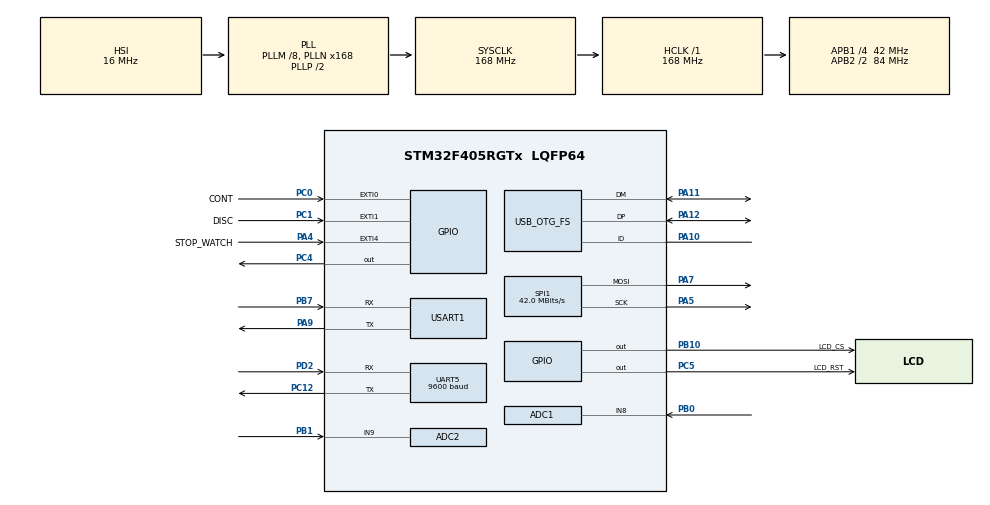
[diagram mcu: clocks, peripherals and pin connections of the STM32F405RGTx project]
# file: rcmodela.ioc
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ADC1.Channel-0\#ChannelRegularConversion=ADC_CHANNEL_8
ADC1.NbrOfConversionFlag=1
ADC1.Rank-0\#ChannelRegularConversion=1
ADC1.SamplingTime-0\#ChannelRegularConversion=ADC_SAMPLETIME_15CYCLES
ADC1.master=1
ADC2.Channel-0\#ChannelRegularConversion=ADC_CHANNEL_9
ADC2.NbrOfConversionFlag=1
ADC2.Rank-0\#ChannelRegularConversion=1
ADC2.SamplingTime-0\#ChannelRegularConversion=ADC_SAMPLETIME_15CYCLES
Dma.Request0=SPI1_TX
Dma.SPI1_TX.0.Direction=DMA_MEMORY_TO_PERIPH
Dma.SPI1_TX.0.FIFOMode=DMA_FIFOMODE_DISABLE
Dma.SPI1_TX.0.Instance=DMA2_Stream3
Dma.SPI1_TX.0.MemDataAlignment=DMA_MDATAALIGN_BYTE
Dma.SPI1_TX.0.MemInc=DMA_MINC_ENABLE
Dma.SPI1_TX.0.Mode=DMA_NORMAL
Dma.SPI1_TX.0.PeriphDataAlignment=DMA_PDATAALIGN_BYTE
Dma.SPI1_TX.0.PeriphInc=DMA_PINC_DISABLE
Dma.SPI1_TX.0.Priority=DMA_PRIORITY_LOW
Mcu.Family=STM32F4
Mcu.Name=STM32F405RGTx
Mcu.Package=LQFP64
NVIC.DMA2_Stream3_IRQn=true\:0\:0\:false\:false\:true\:false\:true\:true
NVIC.EXTI0_IRQn=true\:0\:0\:false\:false\:true\:true\:true\:true
NVIC.EXTI1_IRQn=true\:0\:0\:false\:false\:true\:true\:true\:true
NVIC.EXTI4_IRQn=true\:0\:0\:false\:false\:true\:true\:true\:true
NVIC.PriorityGroup=NVIC_PRIORITYGROUP_4
NVIC.TIM2_IRQn=true\:0\:0\:false\:false\:true\:true\:true\:true
PA10.Mode=OTG/Dual_Role_Device
PA10.Signal=USB_OTG_FS_ID
PA11.Mode=OTG/Dual_Role_Device
PA11.Signal=USB_OTG_FS_DM
PA12.Mode=OTG/Dual_Role_Device
PA12.Signal=USB_OTG_FS_DP
PA4.GPIO_Label=STOP_WATCH
PA4.GPIO_ModeDefaultEXTI=GPIO_MODE_IT_FALLING
PA4.GPIO_PuPd=GPIO_PULLUP
PA4.Signal=GPXTI4
PA5.Mode=TX_Only_Simplex_Unidirect_Master
PA5.Signal=SPI1_SCK
PA7.Mode=TX_Only_Simplex_Unidirect_Master
PA7.Signal=SPI1_MOSI
PA9.Mode=Asynchronous
PA9.Signal=USART1_TX
PB0.Signal=ADCx_IN8
PB1.Signal=ADCx_IN9
PB10.GPIO_Label=LCD_CS
PB10.GPIO_PuPd=GPIO_PULLUP
PB10.GPIO_Speed=GPIO_SPEED_FREQ_HIGH
PB10.PinState=GPIO_PIN_SET
PB10.Signal=GPIO_Output
PB7.Mode=Asynchronous
PB7.Signal=USART1_RX
PC0.GPIO_Label=CONT
PC0.GPIO_ModeDefaultEXTI=GPIO_MODE_IT_FALLING
PC0.GPIO_PuPd=GPIO_PULLUP
PC0.Signal=GPXTI0
PC1.GPIO_Label=DISC
PC1.GPIO_ModeDefaultEXTI=GPIO_MODE_IT_FALLING
PC1.GPIO_PuPd=GPIO_PULLUP
PC1.Signal=GPXTI1
PC12.Mode=Asynchronous
PC12.Signal=UART5_TX
PC4.Signal=GPIO_Output
PC5.GPIO_Label=LCD_RST
PC5.GPIO_PuPd=GPIO_PULLUP
PC5.GPIO_Speed=GPIO_SPEED_FREQ_HIGH
PC5.PinState=GPIO_PIN_SET
PC5.Signal=GPIO_Output
PD2.Mode=Asynchronous
PD2.Signal=UART5_RX
ProjectManager.HeapSize=0x200
ProjectManager.StackSize=0x400
ProjectManager.TargetToolchain=STM32CubeIDE
RCC.48MHZClocksFreq_Value=84000000
RCC.AHBFreq_Value=168000000
RCC.APB1CLKDivider=RCC_HCLK_DIV4
RCC.APB1Freq_Value=42000000
RCC.APB1TimFreq_Value=84000000
RCC.APB2CLKDivider=RCC_HCLK_DIV2
RCC.APB2Freq_Value=84000000
RCC.APB2TimFreq_Value=168000000
RCC.CortexFreq_Value=168000000
RCC.HCLKFreq_Value=168000000
RCC.HSE_VALUE=25000000
RCC.HSI_VALUE=16000000
RCC.LSE_VALUE=32768
RCC.PLLM=8
RCC.PLLN=168
RCC.PLLSourceVirtualString=RCC_PLLSOURCE_HSI
RCC.SYSCLKFreq_VALUE=168000000
RCC.SYSCLKSource=RCC_SYSCLKSOURCE_PLLCLK
RCC.VCOOutputFreq_Value=336000000
SH.ADCx_IN8.0=ADC1_IN8,IN8
SH.ADCx_IN9.0=ADC2_IN9,IN9
SPI1.BaudRatePrescaler=SPI_BAUDRATEPRESCALER_2
SPI1.CalculateBaudRate=42.0 MBits/s
SPI1.Direction=SPI_DIRECTION_2LINES
SPI1.Mode=SPI_MODE_MASTER
SPI1.VirtualType=VM_MASTER
TIM2.Period=10000-1
TIM2.Prescaler=16800-1
UART5.BaudRate=9600
UART5.VirtualMode=Asynchronous
USART1.VirtualMode=VM_ASYNC
VP_TIM2_VS_ClockSourceINT.Mode=Internal
board=custom

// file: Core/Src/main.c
/* USER CODE BEGIN Header */
/**
  ******************************************************************************
  * @file           : main.c
  * @brief          : Main program body
  ******************************************************************************
  * @attention
  *
  * Copyright (c) 2025 STMicroelectronics.
  * All rights reserved.
  *
  * This software is licensed under terms that can be found in the LICENSE file
  * in the root directory of this software component.
  * If no LICENSE file comes with this software, it is provided AS-IS.
  *
  ******************************************************************************
  */
/* USER CODE END Header */
#include "main.h"

/* USER CODE BEGIN Includes */
#include "ILI9341_STM32_DRIVER.h"
#include "ILI9341_GFX.h"
#include "stdio.h"
#include "stdlib.h"
#include "Corrected_U8_Image.h"
#include "ryrl898.h"
#include "stopwatch.h"
#include "allpic.h"

/* USER CODE END Includes */

/* Battery & Sensor Parameters */
#define BATTERY_CAPACITY_AH       2.5f       // 2500 mAh
#define ADC_VREF_VOLTAGE          3.3f       // Reference voltage of ADC
#define ADC_RESOLUTION            4096.0f    // 12-bit ADC
#define VCC_VOLTAGE               3.3f       // ACS712 supply voltage
#define ACS712_SENSITIVITY        0.100f     // V/A for ACS712-20A (100 mV/A)
#define ACS712_OFFSET_VOLTAGE     (VCC_VOLTAGE/2.0f) // zero current voltage
#define TIM2_TICK_PERIOD_S        1.0f       // Timer callback period in seconds

/* USER CODE BEGIN PM */
// #define Total_Cap 2.5           //2500mAh
// #define Vcc 3.3                 //3.6 Max
// #define ACS712_Sensitivity 0.1  //100 mV/A
// #define ADC_Vref 3.3          // max 3.6v
// #define ADC_Resolution 4096  //12-bit Regitser

/* USER CODE END PM */

ADC_HandleTypeDef hadc1;
ADC_HandleTypeDef hadc2;

SPI_HandleTypeDef hspi1;
DMA_HandleTypeDef hdma_spi1_tx;

TIM_HandleTypeDef htim2;

UART_HandleTypeDef huart5;
UART_HandleTypeDef huart1;

uint16_t counter_exti4 =0;

uint8_t mins_stopwatch = 0;
uint8_t sec_stopwatch = 0 ;
uint8_t stopwatch_screen_flag=0;

uint8_t soc_joky; //This Variable will receive the updated Jokey soc sent by the Jokey system via LoRa.

uint8_t soc_rc;
float ACS712_Current;
float ACS712_Voltage;
char timer_text[9];
//char soc_rc_text[3];
char soc_joky_text[3];
char soc_str[10];

void SystemClock_Config(void);
static void MX_GPIO_Init(void);
static void MX_DMA_Init(void);
static void MX_SPI1_Init(void);
static void MX_TIM2_Init(void);
static void MX_UART5_Init(void);
static void MX_USART1_UART_Init(void);
static void MX_ADC1_Init(void);
static void MX_ADC2_Init(void);
void Display_LCD_UI(void);

/* USER CODE BEGIN 0 */
void HAL_GPIO_EXTI_Callback(uint16_t GPIO_Pin)
{
    if(GPIO_Pin == GPIO_PIN_0)  // Check which pin triggered the EXTI
    {
    	//HAL_NVIC_DisableIRQ(EXTI0_IRQn);  // Disable EXTI Line 0 interrupt

        // Your EXTI handling code here
        //do somthing
        //HAL_NVIC_EnableIRQ(EXTI0_IRQn);

    }
    else if(GPIO_Pin == GPIO_PIN_1){

    }
    else if(GPIO_Pin == GPIO_PIN_4){
    HAL_NVIC_DisableIRQ(EXTI4_IRQn);
        HAL_Delay(600);
        if(!HAL_GPIO_ReadPin(STOP_WATCH_GPIO_Port, STOP_WATCH_Pin)){
            counter_exti4 = 0; mins_stopwatch = 0; sec_stopwatch = 0; stopwatch_screen_flag = 0;
            // ILI9341_DrawText("00 : 00", FONT3, 90 , 260, WHITE, BLACK);
            ILI9341_DrawText("00:00", FONT4, 100, 280, WHITE, BLACK);              // Timer text

        }
    	counter_exti4++;
    	if((counter_exti4%2) == 0){
    		stopwatch_screen_flag=0;
    	}

    	else{
    		stopwatch_screen_flag=1;
    	}

    	//        //do somthing
    	//        // Your EXTI ha
        HAL_NVIC_EnableIRQ(EXTI4_IRQn);
    }
}

void HAL_TIM_PeriodElapsedCallback(TIM_HandleTypeDef *htim)
{
    if(htim->Instance == TIM2)
    {
        // Stopwatch update
        if(stopwatch_screen_flag == 1)
        {
            sec_stopwatch++;
            if(sec_stopwatch == 60) { sec_stopwatch = 0; mins_stopwatch++; }
             if(mins_stopwatch == 99) { sec_stopwatch = 0; stopwatch_screen_flag = 0; }

            // sprintf(timer_text,"%d : %d", mins_stopwatch, sec_stopwatch);
            sprintf(timer_text,"%02d : %02d", mins_stopwatch, sec_stopwatch);
            ILI9341_DrawText((const char*)timer_text, FONT4, 100, 280, WHITE, BLACK);
            // ILI9341_DrawText((const char*)timer_text, FONT3, 90 , 260, WHITE, BLACK);
        }

        // Battery SOC calculation
        static float Remain_Cap = BATTERY_CAPACITY_AH; // assume full at boot
        static uint8_t soc_rc_temp = 255;              // force first update
        static uint8_t soc_joky_temp = 255;

        // Read current from ADC
        HAL_ADC_Start(&hadc1);
        HAL_ADC_PollForConversion(&hadc1, 10);
        uint16_t adc_val = HAL_ADC_GetValue(&hadc1);
        HAL_ADC_Stop(&hadc1);

        ACS712_Voltage = ((adc_val * ADC_VREF_VOLTAGE) / ADC_RESOLUTION);
        ACS712_Current = (ACS712_Voltage - ACS712_OFFSET_VOLTAGE) / ACS712_SENSITIVITY;

        // Integrate current to calculate remaining capacity (Ah)
        float delta_Ah = ACS712_Current * (TIM2_TICK_PERIOD_S / 3600.0f);
        Remain_Cap += delta_Ah;

        // Clamp capacity
        if(Remain_Cap > BATTERY_CAPACITY_AH) Remain_Cap = BATTERY_CAPACITY_AH;
        if(Remain_Cap < 0.0f) Remain_Cap = 0.0f;

        soc_rc = (Remain_Cap / BATTERY_CAPACITY_AH) * 100.0f;

        // Update SOC display if changed
        if((uint8_t)soc_rc != soc_rc_temp)
        {
//            sprintf(soc_rc_text, "%d", (uint8_t)soc_rc);
            ILI9341_DrawText((const char*)soc_str, FONT3, 60 ,100, WHITE, BLACK);
            soc_rc_temp = (uint8_t)soc_rc;
            sprintf(soc_str, "%d%%", soc_rc);
            ILI9341_DrawText((const char*)soc_str, FONT3, 70 ,100, WHITE, BLACK);
            if(soc_rc < 10){

                ILI9341_DrawImageAt((const uint8_t*)_less10, 20, 50, 30, 60);                                    // Battery icon

            }
            else if(soc_rc >= 20 && soc_rc < 35){
                ILI9341_DrawImageAt((const uint8_t*)_20, 20, 50, 30, 60);                                    // Battery icon
            }
            else if(soc_rc >= 35 && soc_rc < 50){
                ILI9341_DrawImageAt((const uint8_t*)_35, 20, 50, 30, 60);                                    // Battery icon
            }
            else if(soc_rc >= 50 && soc_rc < 65){
                ILI9341_DrawImageAt((const uint8_t*)_50, 20, 50, 30, 60);                                    // Battery icon
            }
            else if(soc_rc >= 65 && soc_rc < 85){
                ILI9341_DrawImageAt((const uint8_t*)_65, 20, 50, 30, 60);                                    // Battery icon
            }
            else if(soc_rc >= 85 && soc_rc < 100){
                ILI9341_DrawImageAt((const uint8_t*)_85, 20, 50, 30, 60);                                    // Battery icon
            }
            else if(soc_rc >= 100){
                ILI9341_DrawImageAt((const uint8_t*)_100, 20, 50, 30, 60);                                   // Battery icon
            }

        // Update Jokey SOC display if changed
        if(soc_joky != soc_joky_temp)
        {
          soc_joky_temp = soc_joky;
            // sprintf(soc_joky_text, "%d", soc_joky);
            sprintf(soc_joky_text, "%d%%", soc_joky);
            ILI9341_DrawText((const char*)soc_joky_text, FONT3, 180 ,100, WHITE, BLACK);
            //<<==================================================================>>//
            if(soc_joky < 10){

                ILI9341_DrawImageAt((const uint8_t*)_less10, 20, 50, 30, 60);                                    // Battery icon

            }
            else if(soc_joky >= 20 && soc_joky < 35){
                ILI9341_DrawImageAt((const uint8_t*)_20, 20, 50, 30, 60);                                    // Battery icon
            }
            else if(soc_joky >= 35 && soc_joky < 50){
                ILI9341_DrawImageAt((const uint8_t*)_35, 20, 50, 30, 60);                                    // Battery icon
            }
            else if(soc_joky >= 50 && soc_joky < 65){
                ILI9341_DrawImageAt((const uint8_t*)_50, 20, 50, 30, 60);                                    // Battery icon
            }
            else if(soc_joky >= 65 && soc_joky < 85){
                ILI9341_DrawImageAt((const uint8_t*)_65, 20, 50, 30, 60);                                    // Battery icon
            }
            else if(soc_joky >= 85 && soc_joky < 100){
                ILI9341_DrawImageAt((const uint8_t*)_85, 20, 50, 30, 60);                                    // Battery icon
            }
            else if(soc_joky >= 100){
                ILI9341_DrawImageAt((const uint8_t*)_100, 20, 50, 30, 60);                                   // Battery icon
            }

        }
    }
}
}

/* USER CODE END 0 */

int main(void)
{

  /* MCU Configuration--------------------------------------------------------*/

  /* Reset of all peripherals, Initializes the Flash interface and the Systick. */
  HAL_Init();

  /* Configure the system clock */
  SystemClock_Config();

  /* Initialize all configured peripherals */
  MX_GPIO_Init();
  MX_DMA_Init();
  MX_SPI1_Init();
  MX_TIM2_Init();
  MX_UART5_Init();
  MX_USART1_UART_Init();
  MX_ADC1_Init();
  MX_ADC2_Init();
  /* USER CODE BEGIN 2 */
      ILI9341_Init();
      HAL_Delay(100);
    Display_LCD_UI();
      HAL_TIM_Base_Start_IT(&htim2); // Start TIM2 interrupts

  /* USER CODE END 2 */
  uint32_t cont_count=0;
  /* Infinite loop */
  /* USER CODE BEGIN WHILE */
  while (1)
  {

	//code in background the lora and controllers in the poll mode

     /* USER CODE END WHILE */
	  if((!HAL_GPIO_ReadPin(CONT_GPIO_Port, CONT_Pin)) ||(!HAL_GPIO_ReadPin(DISC_GPIO_Port, DISC_Pin)) ){
		  if(!HAL_GPIO_ReadPin(CONT_GPIO_Port, CONT_Pin)){
			  if(cont_count%2==0){
			  lora_send_char((uint8_t)'c');
        soc_joky = lora_receive_char();
			  HAL_Delay(1000);}
			  else {
				  lora_send_char((uint8_t)'0');
          soc_joky = lora_receive_char();
				  HAL_Delay(1000);
			  }
			  cont_count++;

		  }
		  if(!HAL_GPIO_ReadPin(DISC_GPIO_Port, DISC_Pin)){
			  lora_send_char((uint8_t)'d');
        soc_joky = lora_receive_char();

			  HAL_Delay(1000);
		  }

	  }

  }
}

void Display_LCD_UI(void)
{
    // Clear screen
    ILI9341_FillScreen(BLACK);

    // === TOP BAR ===
    ILI9341_DrawText("AMER 1", FONT3, 10, 10, RED, BLACK);                   // Top-left code
    ILI9341_DrawImageAt((const uint8_t*)_4, 210, 10, 20, 20);                                      // Top-right signal icon

    // === BATTERY 1 (Left) ===
    ILI9341_DrawImageAt((const uint8_t*)_less10, 20, 50, 30, 60);                                    // Battery icon
    ILI9341_DrawText("100%", FONT4, 70, 70, WHITE, BLACK);                 // Battery percentage
//    ILI9341_DrawText("SOC_RC", FONT3, 20, 30, WHITE, BLACK);             // Device name

    // === BATTERY 2 (Right) ===
    ILI9341_DrawImageAt((const uint8_t*)_85, 140, 50, 30, 60);                                   // Battery icon
    ILI9341_DrawText("100%", FONT4, 190, 70, WHITE, BLACK);                // Battery percentage
//    ILI9341_DrawText("ROBOT ", FONT3, 140, 30, WHITE, BLACK);          // Device name

    // === DIVIDER ===
//    ILI9341_DrawHLine(0, 220, 240, WHITE);                                          // Horizontal line
//    ILI9341_DrawHLine(0, 221, 240, WHITE);                                          // Horizontal line
//    ILI9341_DrawHLine(0, 222, 240, WHITE);                                          // Horizontal line
//    ILI9341_DrawHLine(0, 222, 240, WHITE);                                          // Horizontal line

    // === STOPWATCH AREA ===
    ILI9341_DrawText("STOP-WATCH", FONT3, 75, 260, WHITE, BLACK);         // Label
    ILI9341_DrawText("00:00", FONT4, 100, 280, WHITE, BLACK);              // Timer text
    ILI9341_DrawImageAt((const uint8_t*)stopwatch, 95, 180, 50, 60);                                   // Stopwatch icon

}

void SystemClock_Config(void)
{
  RCC_OscInitTypeDef RCC_OscInitStruct = {0};
  RCC_ClkInitTypeDef RCC_ClkInitStruct = {0};

  /** Configure the main internal regulator output voltage
  */
  __HAL_RCC_PWR_CLK_ENABLE();
  __HAL_PWR_VOLTAGESCALING_CONFIG(PWR_REGULATOR_VOLTAGE_SCALE1);

  /** Initializes the RCC Oscillators according to the specified parameters
  * in the RCC_OscInitTypeDef structure.
  */
  RCC_OscInitStruct.OscillatorType = RCC_OSCILLATORTYPE_HSI;
  RCC_OscInitStruct.HSIState = RCC_HSI_ON;
  RCC_OscInitStruct.HSICalibrationValue = RCC_HSICALIBRATION_DEFAULT;
  RCC_OscInitStruct.PLL.PLLState = RCC_PLL_ON;
  RCC_OscInitStruct.PLL.PLLSource = RCC_PLLSOURCE_HSI;
  RCC_OscInitStruct.PLL.PLLM = 8;
  RCC_OscInitStruct.PLL.PLLN = 168;
  RCC_OscInitStruct.PLL.PLLP = RCC_PLLP_DIV2;
  RCC_OscInitStruct.PLL.PLLQ = 4;
  if (HAL_RCC_OscConfig(&RCC_OscInitStruct) != HAL_OK)
  {
    Error_Handler();
  }

  /** Initializes the CPU, AHB and APB buses clocks
  */
  RCC_ClkInitStruct.ClockType = RCC_CLOCKTYPE_HCLK|RCC_CLOCKTYPE_SYSCLK
                              |RCC_CLOCKTYPE_PCLK1|RCC_CLOCKTYPE_PCLK2;
  RCC_ClkInitStruct.SYSCLKSource = RCC_SYSCLKSOURCE_PLLCLK;
  RCC_ClkInitStruct.AHBCLKDivider = RCC_SYSCLK_DIV1;
  RCC_ClkInitStruct.APB1CLKDivider = RCC_HCLK_DIV4;
  RCC_ClkInitStruct.APB2CLKDivider = RCC_HCLK_DIV2;

  if (HAL_RCC_ClockConfig(&RCC_ClkInitStruct, FLASH_LATENCY_5) != HAL_OK)
  {
    Error_Handler();
  }
}

static void MX_ADC1_Init(void)
{

  ADC_ChannelConfTypeDef sConfig = {0};

  /** Configure the global features of the ADC (Clock, Resolution, Data Alignment and number of conversion)
  */
  hadc1.Instance = ADC1;
  hadc1.Init.ClockPrescaler = ADC_CLOCK_SYNC_PCLK_DIV4;
  hadc1.Init.Resolution = ADC_RESOLUTION_12B;
  hadc1.Init.ScanConvMode = DISABLE;
  hadc1.Init.ContinuousConvMode = DISABLE;
  hadc1.Init.DiscontinuousConvMode = DISABLE;
  hadc1.Init.ExternalTrigConvEdge = ADC_EXTERNALTRIGCONVEDGE_NONE;
  hadc1.Init.ExternalTrigConv = ADC_SOFTWARE_START;
  hadc1.Init.DataAlign = ADC_DATAALIGN_RIGHT;
  hadc1.Init.NbrOfConversion = 1;
  hadc1.Init.DMAContinuousRequests = DISABLE;
  hadc1.Init.EOCSelection = ADC_EOC_SINGLE_CONV;
  if (HAL_ADC_Init(&hadc1) != HAL_OK)
  {
    Error_Handler();
  }

  /** Configure for the selected ADC regular channel its corresponding rank in the sequencer and its sample time.
  */
  sConfig.Channel = ADC_CHANNEL_8;
  sConfig.Rank = 1;
  sConfig.SamplingTime = ADC_SAMPLETIME_15CYCLES;
  if (HAL_ADC_ConfigChannel(&hadc1, &sConfig) != HAL_OK)
  {
    Error_Handler();
  }

}

static void MX_ADC2_Init(void)
{

  ADC_ChannelConfTypeDef sConfig = {0};

  /** Configure the global features of the ADC (Clock, Resolution, Data Alignment and number of conversion)
  */
  hadc2.Instance = ADC2;
  hadc2.Init.ClockPrescaler = ADC_CLOCK_SYNC_PCLK_DIV4;
  hadc2.Init.Resolution = ADC_RESOLUTION_12B;
  hadc2.Init.ScanConvMode = DISABLE;
  hadc2.Init.ContinuousConvMode = DISABLE;
  hadc2.Init.DiscontinuousConvMode = DISABLE;
  hadc2.Init.ExternalTrigConvEdge = ADC_EXTERNALTRIGCONVEDGE_NONE;
  hadc2.Init.ExternalTrigConv = ADC_SOFTWARE_START;
  hadc2.Init.DataAlign = ADC_DATAALIGN_RIGHT;
  hadc2.Init.NbrOfConversion = 1;
  hadc2.Init.DMAContinuousRequests = DISABLE;
  hadc2.Init.EOCSelection = ADC_EOC_SINGLE_CONV;
  if (HAL_ADC_Init(&hadc2) != HAL_OK)
  {
    Error_Handler();
  }

  /** Configure for the selected ADC regular channel its corresponding rank in the sequencer and its sample time.
  */
  sConfig.Channel = ADC_CHANNEL_9;
  sConfig.Rank = 1;
  sConfig.SamplingTime = ADC_SAMPLETIME_15CYCLES;
  if (HAL_ADC_ConfigChannel(&hadc2, &sConfig) != HAL_OK)
  {
    Error_Handler();
  }

}

static void MX_SPI1_Init(void)
{

  /* SPI1 parameter configuration*/
  hspi1.Instance = SPI1;
  hspi1.Init.Mode = SPI_MODE_MASTER;
  hspi1.Init.Direction = SPI_DIRECTION_2LINES;
  hspi1.Init.DataSize = SPI_DATASIZE_8BIT;
  hspi1.Init.CLKPolarity = SPI_POLARITY_LOW;
  hspi1.Init.CLKPhase = SPI_PHASE_1EDGE;
  hspi1.Init.NSS = SPI_NSS_SOFT;
  hspi1.Init.BaudRatePrescaler = SPI_BAUDRATEPRESCALER_2;
  hspi1.Init.FirstBit = SPI_FIRSTBIT_MSB;
  hspi1.Init.TIMode = SPI_TIMODE_DISABLE;
  hspi1.Init.CRCCalculation = SPI_CRCCALCULATION_DISABLE;
  hspi1.Init.CRCPolynomial = 10;
  if (HAL_SPI_Init(&hspi1) != HAL_OK)
  {
    Error_Handler();
  }

}

static void MX_TIM2_Init(void)
{

  TIM_ClockConfigTypeDef sClockSourceConfig = {0};
  TIM_MasterConfigTypeDef sMasterConfig = {0};

  htim2.Instance = TIM2;
  htim2.Init.Prescaler = 16800-1;
  htim2.Init.CounterMode = TIM_COUNTERMODE_UP;
  htim2.Init.Period = 10000-1;
  htim2.Init.ClockDivision = TIM_CLOCKDIVISION_DIV1;
  htim2.Init.AutoReloadPreload = TIM_AUTORELOAD_PRELOAD_DISABLE;
  if (HAL_TIM_Base_Init(&htim2) != HAL_OK)
  {
    Error_Handler();
  }
  sClockSourceConfig.ClockSource = TIM_CLOCKSOURCE_INTERNAL;
  if (HAL_TIM_ConfigClockSource(&htim2, &sClockSourceConfig) != HAL_OK)
  {
    Error_Handler();
  }
  sMasterConfig.MasterOutputTrigger = TIM_TRGO_RESET;
  sMasterConfig.MasterSlaveMode = TIM_MASTERSLAVEMODE_DISABLE;
  if (HAL_TIMEx_MasterConfigSynchronization(&htim2, &sMasterConfig) != HAL_OK)
  {
    Error_Handler();
  }

}

static void MX_UART5_Init(void)
{

  huart5.Instance = UART5;
  huart5.Init.BaudRate = 9600;
  huart5.Init.WordLength = UART_WORDLENGTH_8B;
  huart5.Init.StopBits = UART_STOPBITS_1;
  huart5.Init.Parity = UART_PARITY_NONE;
  huart5.Init.Mode = UART_MODE_TX_RX;
  huart5.Init.HwFlowCtl = UART_HWCONTROL_NONE;
  huart5.Init.OverSampling = UART_OVERSAMPLING_16;
  if (HAL_UART_Init(&huart5) != HAL_OK)
  {
    Error_Handler();
  }

}

static void MX_USART1_UART_Init(void)
{

  huart1.Instance = USART1;
  huart1.Init.BaudRate = 115200;
  huart1.Init.WordLength = UART_WORDLENGTH_8B;
  huart1.Init.StopBits = UART_STOPBITS_1;
  huart1.Init.Parity = UART_PARITY_NONE;
  huart1.Init.Mode = UART_MODE_TX_RX;
  huart1.Init.HwFlowCtl = UART_HWCONTROL_NONE;
  huart1.Init.OverSampling = UART_OVERSAMPLING_16;
  if (HAL_UART_Init(&huart1) != HAL_OK)
  {
    Error_Handler();
  }

}

static void MX_DMA_Init(void)
{

  /* DMA controller clock enable */
  __HAL_RCC_DMA2_CLK_ENABLE();

  /* DMA interrupt init */
  /* DMA2_Stream3_IRQn interrupt configuration */
  HAL_NVIC_SetPriority(DMA2_Stream3_IRQn, 0, 0);
  HAL_NVIC_EnableIRQ(DMA2_Stream3_IRQn);

}

static void MX_GPIO_Init(void)
{
  GPIO_InitTypeDef GPIO_InitStruct = {0};

  /* GPIO Ports Clock Enable */
  __HAL_RCC_GPIOC_CLK_ENABLE();
  __HAL_RCC_GPIOA_CLK_ENABLE();
  __HAL_RCC_GPIOB_CLK_ENABLE();
  __HAL_RCC_GPIOD_CLK_ENABLE();

  /*Configure GPIO pin Output Level */
  HAL_GPIO_WritePin(GPIOC, LCD_DC_Pin|LCD_RST_Pin, GPIO_PIN_SET);

  /*Configure GPIO pin Output Level */
  HAL_GPIO_WritePin(LCD_CS_GPIO_Port, LCD_CS_Pin, GPIO_PIN_SET);

  /*Configure GPIO pins : CONT_Pin DISC_Pin */
  GPIO_InitStruct.Pin = CONT_Pin|DISC_Pin;
  GPIO_InitStruct.Mode = GPIO_MODE_IT_FALLING;
  GPIO_InitStruct.Pull = GPIO_PULLUP;
  HAL_GPIO_Init(GPIOC, &GPIO_InitStruct);

  /*Configure GPIO pin : STOP_WATCH_Pin */
  GPIO_InitStruct.Pin = STOP_WATCH_Pin;
  GPIO_InitStruct.Mode = GPIO_MODE_IT_FALLING;
  GPIO_InitStruct.Pull = GPIO_PULLUP;
  HAL_GPIO_Init(STOP_WATCH_GPIO_Port, &GPIO_InitStruct);

  /*Configure GPIO pins : LCD_DC_Pin LCD_RST_Pin */
  GPIO_InitStruct.Pin = LCD_DC_Pin|LCD_RST_Pin;
  GPIO_InitStruct.Mode = GPIO_MODE_OUTPUT_PP;
  GPIO_InitStruct.Pull = GPIO_PULLUP;
  GPIO_InitStruct.Speed = GPIO_SPEED_FREQ_HIGH;
  HAL_GPIO_Init(GPIOC, &GPIO_InitStruct);

  /*Configure GPIO pin : LCD_CS_Pin */
  GPIO_InitStruct.Pin = LCD_CS_Pin;
  GPIO_InitStruct.Mode = GPIO_MODE_OUTPUT_PP;
  GPIO_InitStruct.Pull = GPIO_PULLUP;
  GPIO_InitStruct.Speed = GPIO_SPEED_FREQ_HIGH;
  HAL_GPIO_Init(LCD_CS_GPIO_Port, &GPIO_InitStruct);

  /* EXTI interrupt init*/
  HAL_NVIC_SetPriority(EXTI0_IRQn, 0, 0);
  HAL_NVIC_EnableIRQ(EXTI0_IRQn);

  HAL_NVIC_SetPriority(EXTI1_IRQn, 0, 0);
  HAL_NVIC_EnableIRQ(EXTI1_IRQn);

  HAL_NVIC_SetPriority(EXTI4_IRQn, 0, 0);
  HAL_NVIC_EnableIRQ(EXTI4_IRQn);

}

void Error_Handler(void)
{
  __disable_irq();
  while (1)
  {
  }
}
